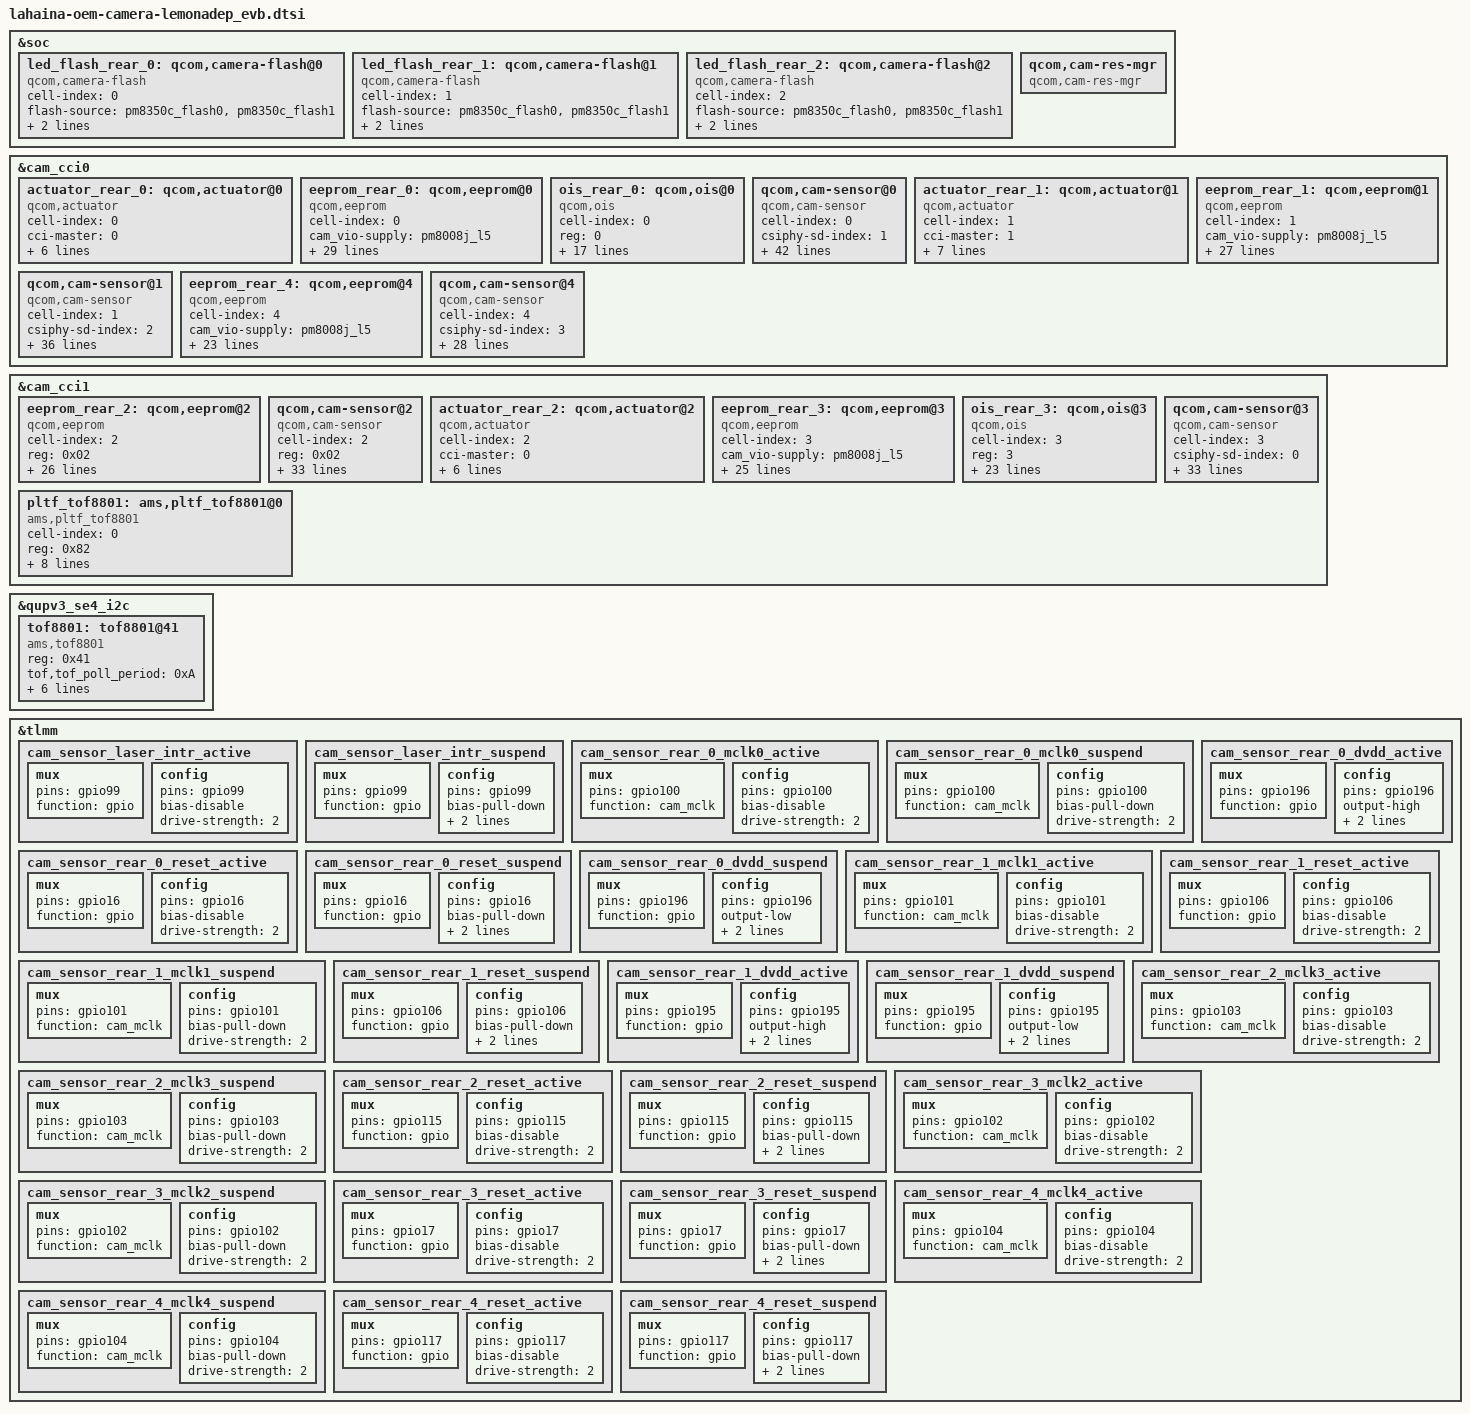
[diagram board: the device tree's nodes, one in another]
#include <dt-bindings/clock/qcom,camcc-lahaina.h>

&soc {
    led_flash_rear_0: qcom,camera-flash@0 {
        cell-index = <0>;
        compatible = "qcom,camera-flash";
        flash-source = <&pm8350c_flash0 &pm8350c_flash1>;
        torch-source = <&pm8350c_torch0 &pm8350c_torch1>;
        switch-source = <&pm8350c_switch2>;
        status = "ok";
    };

    led_flash_rear_1: qcom,camera-flash@1 {
        cell-index = <1>;
        compatible = "qcom,camera-flash";
        flash-source = <&pm8350c_flash0 &pm8350c_flash1>;
        torch-source = <&pm8350c_torch0 &pm8350c_torch1>;
        switch-source = <&pm8350c_switch2>;
        status = "ok";
    };

    led_flash_rear_2: qcom,camera-flash@2 {
        cell-index = <2>;
        compatible = "qcom,camera-flash";
        flash-source = <&pm8350c_flash0 &pm8350c_flash1>;
        torch-source = <&pm8350c_torch0 &pm8350c_torch1>;
        switch-source = <&pm8350c_switch2>;
        status = "ok";
    };

    qcom,cam-res-mgr {
        compatible = "qcom,cam-res-mgr";
        status = "ok";
    };
};

&cam_cci0 {

    actuator_rear_0: qcom,actuator@0 {
        cell-index = <0>;
        compatible = "qcom,actuator";
        cci-master = <0>;
        cam_vaf-supply = <&pm8008i_l7>;
        regulator-names = "cam_vaf";
        rgltr-cntrl-support;
        rgltr-min-voltage = <2800000>;
        rgltr-max-voltage = <2800000>;
        rgltr-load-current = <1000000>;
    };

    eeprom_rear_0: qcom,eeprom@0 {
        cell-index = <0>;
        compatible = "qcom,eeprom";
        cam_vio-supply = <&pm8008j_l5>;
        cam_vana-supply = <&pm8350c_bob>;
        cam_v_custom1-supply = <&pm8008i_l6>;
        cam_clk-supply = <&cam_cc_titan_top_gdsc>;
        cam_vaf-supply = <&pm8008i_l7>;
        regulator-names = "cam_vio", "cam_vana", "cam_v_custom1", "cam_clk", "cam_vaf";
        rgltr-cntrl-support;
        rgltr-min-voltage = <0 3200000 2700000 0 2800000>;
        rgltr-max-voltage = <0 3960000 3000000 0 2800000>;
        rgltr-load-current = <200000 2000000 1000000 0 1000000>;
        gpio-no-mux = <0>;
        pinctrl-names = "cam_default", "cam_suspend";
        pinctrl-0 = <&cam_sensor_rear_0_mclk0_active
                     &cam_sensor_rear_0_reset_active
                     &cam_sensor_rear_0_dvdd_active>;
        pinctrl-1 = <&cam_sensor_rear_0_mclk0_suspend
                     &cam_sensor_rear_0_reset_suspend
                     &cam_sensor_rear_0_dvdd_suspend>;
        gpios = <&tlmm 100 0>,
                <&tlmm 16 0>,
                <&tlmm 196 0>;
        gpio-reset = <1>;
        gpio-vdig = <2>;
        gpio-req-tbl-num = <0 1 2>;
        gpio-req-tbl-flags = <1 0 0>;
        gpio-req-tbl-label = "CAMIF_MCLK0",
                    "CAM_RESET0","CAM_DVDD0";
        cci-master = <0>;
        status = "ok";
        clocks = <&clock_camcc CAM_CC_MCLK0_CLK>;
        clock-names = "cam_clk";
        clock-cntl-level = "nominal";
        clock-rates = <19200000>;
    };

    ois_rear_0: qcom,ois@0{
        cell-index = <0>;
        reg = <0>;
        compatible = "qcom,ois";
        cam_vio-supply = <&pm8008j_l5>;
        cam_vaf-supply = <&pm8008i_l7>;
        cam_v_custom1-supply = <&pm8008i_l6>;
        regulator-names ="cam_vio","cam_vaf","cam_v_custom1";
        rgltr-cntrl-support;
        rgltr-min-voltage = <0 2800000 2700000>;
        rgltr-max-voltage = <0 2800000 3000000>;
        rgltr-load-current = <200000 1000000 2000000>;
        cci-master = <0>;
        ois_gyro,position=<3>;
        ois_gyro,type=<6>;
        ois,type=<0>;
        ois,name="LC898128";
        ois_module,vendor=<6>;
        ois_actuator,vednor=<1>;
        ois,fw=<1>;
        status = "ok";
    };

/*wide camera*/
    qcom,cam-sensor@0 {
        cell-index = <0>;
        compatible = "qcom,cam-sensor";
        csiphy-sd-index = <1>;
        sensor-position-roll = <90>;
        sensor-position-pitch = <0>;
        sensor-position-yaw = <180>;
        actuator-src = <&actuator_rear_0>;
        eeprom-src = <&eeprom_rear_0>;
        led-flash-src = <&led_flash_rear_0>;
        ois-src = <&ois_rear_0>;
        cam_vio-supply = <&pm8008j_l5>;
        cam_vana-supply = <&pm8350c_bob>;
        cam_v_custom1-supply = <&pm8008i_l6>;
        cam_clk-supply = <&cam_cc_titan_top_gdsc>;
        cam_bob-supply = <&pm8350c_bob>;
        cam_vaf-supply = <&pm8008i_l7>;
        regulator-names = "cam_vio", "cam_vana", "cam_v_custom1", "cam_clk", "cam_bob", "cam_vaf";
        rgltr-cntrl-support;
        rgltr-min-voltage = <0 3200000 2700000 0 3200000 2700000>;
        rgltr-max-voltage = <0 3960000 3000000 0 3960000 3000000>;
        rgltr-load-current = <200000 2000000 1000000 0 2000000 1000000>;
        gpio-no-mux = <0>;
        pinctrl-names = "cam_default", "cam_suspend";
        pinctrl-0 = <&cam_sensor_rear_0_mclk0_active
                     &cam_sensor_rear_0_reset_active
                     &cam_sensor_rear_0_dvdd_active>;
        pinctrl-1 = <&cam_sensor_rear_0_mclk0_suspend
                     &cam_sensor_rear_0_reset_suspend
                     &cam_sensor_rear_0_dvdd_suspend>;
        gpios = <&tlmm 100 0>,
                <&tlmm 16 0>,
                <&tlmm 196 0>;
        gpio-reset = <1>;
        gpio-vdig = <2>;
        gpio-req-tbl-num = <0 1 2>;
        gpio-req-tbl-flags = <1 0 0>;
        gpio-req-tbl-label = "CAMIF_MCLK0","CAM_RESET0","CAM_DVDD0";
        cci-master = <0>;
        status = "ok";
        clocks = <&clock_camcc CAM_CC_MCLK0_CLK>;
        clock-names = "cam_clk";
        clock-cntl-level = "nominal";
        clock-rates = <19200000>;
        is-support-laser = <1>;
        at-current-support = <1>;
    };

    actuator_rear_1: qcom,actuator@1 {
        cell-index = <1>;
        compatible = "qcom,actuator";
        cci-master = <1>;
        cam_vaf-supply = <&pm8008j_l3>;
        regulator-names = "cam_vaf";
        rgltr-cntrl-support;
        rgltr-min-voltage = <2800000>;
        rgltr-max-voltage = <2800000>;
        rgltr-load-current = <1000000>;
        need-check-pid;
    };

    eeprom_rear_1: qcom,eeprom@1 {
        cell-index = <1>;
        compatible = "qcom,eeprom";
        cam_vio-supply = <&pm8008j_l5>;
        cam_vana-supply = <&pm8350c_bob>;
        cam_clk-supply = <&cam_cc_titan_top_gdsc>;
        cam_vaf-supply = <&pm8008j_l3>;
        regulator-names = "cam_vio", "cam_vana", "cam_clk", "cam_vaf";
        rgltr-cntrl-support;
        rgltr-min-voltage = <0 3200000 0 2800000>;
        rgltr-max-voltage = <0 3960000 0 2800000>;
        rgltr-load-current = <200000 2000000 0 1000000>;
        gpio-no-mux = <0>;
        pinctrl-names = "cam_default", "cam_suspend";
        pinctrl-0 = <&cam_sensor_rear_1_mclk1_active
                     &cam_sensor_rear_1_reset_active
                     &cam_sensor_rear_1_dvdd_active>;
        pinctrl-1 = <&cam_sensor_rear_1_mclk1_suspend
                     &cam_sensor_rear_1_reset_suspend
                     &cam_sensor_rear_1_dvdd_suspend>;
        gpios = <&tlmm 101 0>,
                <&tlmm 106 0>,
                <&tlmm 195 0>;
        gpio-reset = <1>;
        gpio-vdig = <2>;
        gpio-req-tbl-num = <0 1 2>;
        gpio-req-tbl-flags = <1 0 0>;
        gpio-req-tbl-label = "CAMIF_MCLK1",
                    "CAM_RESET1","CAM_DVDD1";
        cci-master = <1>;
        status = "ok";
        clocks = <&clock_camcc CAM_CC_MCLK1_CLK>;
        clock-names = "cam_clk";
        clock-cntl-level = "nominal";
        clock-rates = <19200000>;
    };

    /*ultra wide camera*/
    qcom,cam-sensor@1 {
        cell-index = <1>;
        compatible = "qcom,cam-sensor";
        csiphy-sd-index = <2>;
        sensor-position-roll = <90>;
        sensor-position-pitch = <0>;
        sensor-position-yaw = <180>;
        eeprom-src = <&eeprom_rear_1>;
        actuator-src = <&actuator_rear_1>;
        led-flash-src = <&led_flash_rear_1>;
        cam_vio-supply = <&pm8008j_l5>;
        cam_vana-supply = <&pm8350c_bob>;
        cam_clk-supply = <&cam_cc_titan_top_gdsc>;
        cam_bob-supply = <&pm8350c_bob>;
        regulator-names = "cam_vio", "cam_vana", "cam_clk", "cam_bob";
        rgltr-cntrl-support;
        rgltr-min-voltage = <0 3200000 0 3200000>;
        rgltr-max-voltage = <0 3960000 0 3960000>;
        rgltr-load-current = <200000 2000000 0 2000000>;
        gpio-no-mux = <0>;
        pinctrl-names = "cam_default", "cam_suspend";
        pinctrl-0 = <&cam_sensor_rear_1_mclk1_active
                     &cam_sensor_rear_1_reset_active
                     &cam_sensor_rear_1_dvdd_active>;
        pinctrl-1 = <&cam_sensor_rear_1_mclk1_suspend
                     &cam_sensor_rear_1_reset_suspend
                     &cam_sensor_rear_1_dvdd_suspend>;
        gpios = <&tlmm 101 0>,
                <&tlmm 106 0>,
                <&tlmm 195 0>;
        gpio-reset = <1>;
        gpio-vdig = <2>;
        gpio-req-tbl-num = <0 1 2>;
        gpio-req-tbl-flags = <1 0 0>;
        gpio-req-tbl-label = "CAMIF_MCLK1","CAM_RESET1","CAM_DVDD1";
        cci-master = <1>;
        status = "ok";
        clocks = <&clock_camcc CAM_CC_MCLK1_CLK>;
        clock-names = "cam_clk";
        clock-cntl-level = "nominal";
        clock-rates = <19200000>;
        at-current-support = <1>;
        is-diff-af-support = <1>;
    };

    eeprom_rear_4: qcom,eeprom@4 {
        cell-index = <4>;
        compatible = "qcom,eeprom";
        cam_vio-supply = <&pm8008j_l5>;
        cam_vdig-supply = <&pm8008i_l2>;
        cam_clk-supply = <&cam_cc_titan_top_gdsc>;
        cam_vana-supply = <&pm8008i_l5>;
        regulator-names = "cam_vio", "cam_vdig", "cam_clk", "cam_vana";
        rgltr-cntrl-support;
        rgltr-min-voltage = <0 1170000 0 2800000>;
        rgltr-max-voltage = <0 2040000 0 2800000>;
        rgltr-load-current = <200000 680000 0 50000>;
        gpio-no-mux = <0>;
        pinctrl-names = "cam_default", "cam_suspend";
        pinctrl-0 = <&cam_sensor_rear_4_mclk4_active
                     &cam_sensor_rear_4_reset_active>;
        pinctrl-1 = <&cam_sensor_rear_4_mclk4_suspend
                     &cam_sensor_rear_4_reset_suspend>;
        gpios = <&tlmm 104 0>,
                <&tlmm 117 0>;
        gpio-reset = <1>;
        gpio-req-tbl-num = <0 1>;
        gpio-req-tbl-flags = <1 0>;
        gpio-req-tbl-label = "CAMIF_MCLK4",
                    "CAM_RESET4";
        cci-master = <1>;
        status = "ok";
        clocks = <&clock_camcc CAM_CC_MCLK4_CLK>;
        clock-names = "cam_clk";
        clock-cntl-level = "nominal";
        clock-rates = <19200000>;
    };

    /*forth_camera*/
    qcom,cam-sensor@4 {
        cell-index = <4>;
        compatible = "qcom,cam-sensor";
        csiphy-sd-index = <3>;
        eeprom-src = <&eeprom_rear_4>;
        sensor-position-roll = <90>;
        sensor-position-pitch = <0>;
        sensor-position-yaw = <180>;
        cam_vio-supply = <&pm8008j_l5>;
        cam_vdig-supply = <&pm8008i_l2>;
        cam_clk-supply = <&cam_cc_titan_top_gdsc>;
        cam_vana-supply = <&pm8008i_l5>;
        regulator-names = "cam_vio", "cam_vdig", "cam_clk", "cam_vana";
        rgltr-cntrl-support;
        rgltr-min-voltage = <0 1200000 0 2800000>;
        rgltr-max-voltage = <0 1200000 0 2800000>;
        rgltr-load-current = <200000 680000 0 50000>;
        gpio-no-mux = <0>;
        pinctrl-names = "cam_default", "cam_suspend";
        pinctrl-0 = <&cam_sensor_rear_4_mclk4_active
                     &cam_sensor_rear_4_reset_active>;
        pinctrl-1 = <&cam_sensor_rear_4_mclk4_suspend
                     &cam_sensor_rear_4_reset_suspend>;
        gpios = <&tlmm 104 0>,
                <&tlmm 117 0>;
        gpio-reset = <1>;
        gpio-req-tbl-num = <0 1>;
        gpio-req-tbl-flags = <1 0>;
        gpio-req-tbl-label = "CAMIF_MCLK4", "CAM_RESET4";
        cci-master = <1>;
        status = "ok";
        clocks = <&clock_camcc CAM_CC_MCLK4_CLK>;
        clock-names = "cam_clk";
        clock-cntl-level = "nominal";
        clock-rates = <19200000>;
    };
};

&cam_cci1 {
    eeprom_rear_2: qcom,eeprom@2 {
        cell-index = <2>;
        compatible = "qcom,eeprom";
        reg = <0x02>;
        cam_vio-supply = <&pm8008j_l5>;
        cam_vana-supply = <&pm8008i_l4>;
        cam_vdig-supply = <&pm8008j_l2>;
        cam_clk-supply = <&cam_cc_titan_top_gdsc>;
        regulator-names = "cam_vio", "cam_vana", "cam_vdig","cam_clk";
        rgltr-cntrl-support;
        rgltr-min-voltage = <0 2700000 950000 0>;
        rgltr-max-voltage = <0 2900000 1150000 0>;
        rgltr-load-current = <200000 35000 301000 0>;
        gpio-no-mux = <0>;
        pinctrl-names = "cam_default", "cam_suspend";
        pinctrl-0 = <&cam_sensor_rear_2_mclk3_active
                     &cam_sensor_rear_2_reset_active>;
        pinctrl-1 = <&cam_sensor_rear_2_mclk3_suspend
                     &cam_sensor_rear_2_reset_suspend>;
        gpios = <&tlmm 103 0>,
                <&tlmm 115 0>;
        gpio-reset = <1>;
        gpio-req-tbl-num = <0 1>;
        gpio-req-tbl-flags = <1 0>;
        gpio-req-tbl-label = "CAM_front_MCLK","CAM_front_RESET";
        sensor-mode = <0>;
        cci-master = <1>;
        status = "ok";
        clocks = <&clock_camcc CAM_CC_MCLK3_CLK>;
        clock-names = "cam_clk";
        clock-cntl-level = "nominal";
        clock-rates = <19200000>;
    };

/*front camera*/
    qcom,cam-sensor@2 {
        cell-index = <2>;
        compatible = "qcom,cam-sensor";
        reg = <0x02>;
        csiphy-sd-index = <5>;
        sensor-position-roll = <270>;
        sensor-position-pitch = <0>;
        sensor-position-yaw = <0>;
        eeprom-src = <&eeprom_rear_2>;
        cam_vio-supply = <&pm8008j_l5>;
        cam_vana-supply = <&pm8008i_l4>;
        cam_vdig-supply = <&pm8008j_l2>;
        cam_clk-supply = <&cam_cc_titan_top_gdsc>;
        cam_bob-supply = <&pm8350c_bob>;
        regulator-names = "cam_vio", "cam_vana", "cam_vdig","cam_clk", "cam_bob";
        rgltr-cntrl-support;
        rgltr-min-voltage = <0 2700000 950000 0 3200000>;
        rgltr-max-voltage = <0 2900000 1150000 0 3960000>;
        rgltr-load-current = <200000 35000 301000 0 2000000>;
        gpio-no-mux = <0>;
        pinctrl-names = "cam_default", "cam_suspend";
        pinctrl-0 = <&cam_sensor_rear_2_mclk3_active
                     &cam_sensor_rear_2_reset_active>;
        pinctrl-1 = <&cam_sensor_rear_2_mclk3_suspend
                     &cam_sensor_rear_2_reset_suspend>;
        gpios = <&tlmm 103 0>,
                <&tlmm 115 0>;
        gpio-reset = <1>;
        gpio-req-tbl-num = <0 1>;
        gpio-req-tbl-flags = <1 0>;
        gpio-req-tbl-label = "CAM_front_MCLK","CAM_front_RESET";
        sensor-mode = <0>;
        cci-master = <1>;
        status = "ok";
        clocks = <&clock_camcc CAM_CC_MCLK3_CLK>;
        clock-names = "cam_clk";
        clock-cntl-level = "nominal";
        clock-rates = <19200000>;
    };

    actuator_rear_2: qcom,actuator@2 {
        cell-index = <2>;
        compatible = "qcom,actuator";
        cci-master = <0>;
        cam_vaf-supply = <&pm8008j_l7>;
        regulator-names = "cam_vaf";
        rgltr-cntrl-support;
        rgltr-min-voltage = <2800000>;
        rgltr-max-voltage = <2800000>;
        rgltr-load-current = <1000000>;
    };

    eeprom_rear_3: qcom,eeprom@3 {
        cell-index = <3>;
        compatible = "qcom,eeprom";
        cam_vio-supply = <&pm8008j_l5>;
        cam_vana-supply = <&pm8008i_l3>;
        cam_vdig-supply = <&pm8008i_l1>;
        cam_clk-supply = <&cam_cc_titan_top_gdsc>;
        cam_vaf-supply = <&pm8008j_l7>;
        regulator-names = "cam_vio", "cam_vana", "cam_vdig",
            "cam_clk", "cam_vaf";
        rgltr-cntrl-support;
        rgltr-min-voltage = <0 2700000 950000 0 2800000>;
        rgltr-max-voltage = <0 2900000 1150000 0 2800000>;
        rgltr-load-current = <200000 52000 140000 0 1000000>;
        gpio-no-mux = <0>;
        pinctrl-names = "cam_default", "cam_suspend";
        pinctrl-0 = <&cam_sensor_rear_3_mclk2_active
                     &cam_sensor_rear_3_reset_active>;
        pinctrl-1 = <&cam_sensor_rear_3_mclk2_suspend
                     &cam_sensor_rear_3_reset_suspend>;
        gpios = <&tlmm 102 0>,
                <&tlmm 17 0>;
        gpio-reset = <1>;
        gpio-req-tbl-num = <0 1>;
        gpio-req-tbl-flags = <1 0>;
        gpio-req-tbl-label = "CAMIF_MCLK2", "CAM_RESET2";
        cci-master = <0>;
        status = "ok";
        clocks = <&clock_camcc CAM_CC_MCLK2_CLK>;
        clock-names = "cam_clk";
        clock-cntl-level = "nominal";
        clock-rates = <19200000>;
    };

    ois_rear_3: qcom,ois@3{
        cell-index = <3>;
        reg = <3>;
        compatible = "qcom,ois";
        cam_vio-supply = <&pm8008j_l5>;
        cam_vana-supply = <&pm8008i_l3>;
        cam_vdig-supply = <&pm8008i_l1>;
        cam_vaf-supply = <&pm8008j_l6>;
        cam_v_custom1-supply = <&pm8008i_l7>;
        cam_v_custom2-supply = <&pm8008i_l6>;
        regulator-names = "cam_vio","cam_vana","cam_vdig","cam_vaf","cam_v_custom1","cam_v_custom2";
        rgltr-cntrl-support;
        rgltr-min-voltage = <0 2700000 950000 2700000 2800000 2700000>;
        rgltr-max-voltage = <0 2900000 1150000 3000000 2800000 3000000>;
        rgltr-load-current = <200000 52000 140000 2000000 1000000 2000000>;
        cci-master = <0>;
        ois_gyro,position=<3>;
        ois_gyro,type=<3>;
        ois,type=<1>;
        ois,name="LC898124";
        ois_module,vendor=<0>;
        ois_actuator,vednor=<0>;
        ois,fw=<1>;
        status = "ok";
    };

/*tele camera*/
    qcom,cam-sensor@3 {
        cell-index = <3>;
        compatible = "qcom,cam-sensor";
        csiphy-sd-index = <0>;
        sensor-position-roll = <90>;
        sensor-position-pitch = <0>;
        sensor-position-yaw = <180>;
        eeprom-src = <&eeprom_rear_3>;
        actuator-src = <&actuator_rear_2>;
        led-flash-src = <&led_flash_rear_2>;
        ois-src = <&ois_rear_3>;
        cam_vio-supply = <&pm8008j_l5>;
        cam_vana-supply = <&pm8008i_l3>;
        cam_vdig-supply = <&pm8008i_l1>;
        cam_clk-supply = <&cam_cc_titan_top_gdsc>;
        cam_bob-supply = <&pm8350c_bob>;
        regulator-names = "cam_vio", "cam_vana", "cam_vdig",
            "cam_clk", "cam_bob";
        rgltr-cntrl-support;
        rgltr-min-voltage = <0 2700000 950000 0 3200000>;
        rgltr-max-voltage = <0 2900000 1150000 0 3960000>;
        rgltr-load-current = <200000 52000 140000 0 2000000>;
        gpio-no-mux = <0>;
        pinctrl-names = "cam_default", "cam_suspend";
        pinctrl-0 = <&cam_sensor_rear_3_mclk2_active
                     &cam_sensor_rear_3_reset_active>;
        pinctrl-1 = <&cam_sensor_rear_3_mclk2_suspend
                     &cam_sensor_rear_3_reset_suspend>;
        gpios = <&tlmm 102 0>,
                <&tlmm 17 0>;
        gpio-reset = <1>;
        gpio-req-tbl-num = <0 1>;
        gpio-req-tbl-flags = <1 0>;
        gpio-req-tbl-label = "CAMIF_MCLK2", "CAM_RESET2";
        cci-master = <0>;
        status = "ok";
        clocks = <&clock_camcc CAM_CC_MCLK2_CLK>;
        clock-names = "cam_clk";
        clock-cntl-level = "nominal";
        clock-rates = <19200000>;
    };

pltf_tof8801: ams,pltf_tof8801@0 {
        cell-index = <0>;
        reg = <0x82>;
        compatible = "ams,pltf_tof8801";
        cam_vio-supply = <&pm8008j_l5>;
        regulator-names = "cam_vio";
        rgltr-cntrl-support;
        rgltr-min-voltage = <0>;
        rgltr-max-voltage = <0>;
        rgltr-load-current = <5000>;
        cci-device = <1>;
        cci-master = <1>;
        status = "ok";
	};
};

&qupv3_se4_i2c {
    tof8801: tof8801@41 {
        compatible = "ams,tof8801";
        reg = <0x41>;
        tof,tof_poll_period = <0xA>; /*poll period (100 usec)*/
        laser_vdd-supply = <&pm8008j_l4>;
        pinctrl-names = "laser_default", "laser_suspend";
        pinctrl-0 = <&cam_sensor_laser_intr_active>;
        pinctrl-1 = <&cam_sensor_laser_intr_suspend>;
        interrupt-parent = <&tlmm>;
        enable-gpios = <&tlmm 126 0>;
        irq-gpios = <&tlmm 99 0>;
    };

};

&tlmm {
     cam_sensor_laser_intr_active:cam_sensor_laser_intr_active {
        mux {
            pins = "gpio99";
            function = "gpio";
        };

        config {
            pins = "gpio99";
            bias-disable; /* No PULL */
            drive-strength = <2>; /* 2 MA */
        };
    };

    cam_sensor_laser_intr_suspend: cam_sensor_laser_intr_suspend {
        mux {
            pins = "gpio99";
            function = "gpio";
        };

        config {
            pins = "gpio99";
            bias-pull-down; /* PULL DOWN */
            drive-strength = <2>; /* 2 MA */
            output-low;
        };
    };
    cam_sensor_rear_0_mclk0_active: cam_sensor_rear_0_mclk0_active {
        /* MCLK0 */
        mux {
            pins = "gpio100";
            function = "cam_mclk";
        };

        config {
            pins = "gpio100";
            bias-disable; /* No PULL */
            drive-strength = <2>; /* 2 MA */
        };
    };

    cam_sensor_rear_0_mclk0_suspend: cam_sensor_rear_0_mclk0_suspend {
        /* MCLK0 */
        mux {
            pins = "gpio100";
            function = "cam_mclk";
        };

        config {
            pins = "gpio100";
            bias-pull-down; /* PULL DOWN */
            drive-strength = <2>; /* 2 MA */
        };
    };

    cam_sensor_rear_0_reset_active: cam_sensor_rear_0_reset_active {
        /* RESET REARAUX */
        mux {
            pins = "gpio16";
            function = "gpio";
        };

        config {
            pins = "gpio16";
            bias-disable; /* No PULL */
            drive-strength = <2>; /* 2 MA */
        };
    };

    cam_sensor_rear_0_reset_suspend: cam_sensor_rear_0_reset_suspend {
        /* RESET REARAUX */
        mux {
            pins = "gpio16";
            function = "gpio";
        };

        config {
            pins = "gpio16";
            bias-pull-down; /* PULL DOWN */
            drive-strength = <2>; /* 2 MA */
            output-low;
        };
    };

    cam_sensor_rear_0_dvdd_active: cam_sensor_rear_0_dvdd_active {
        /* RESET, STANDBY */
        mux {
            pins = "gpio196";
            function = "gpio";
        };

        config {
            pins = "gpio196";
            output-high;
            bias-pull-up;
            drive-strength = <2>; /* 2 MA */
        };
    };

    cam_sensor_rear_0_dvdd_suspend: cam_sensor_rear_0_dvdd_suspend {
        /* RESET, STANDBY */
        mux {
            pins = "gpio196";
            function = "gpio";
        };

        config {
            pins = "gpio196";
            output-low; /* active low reset */
            bias-pull-down;
            drive-strength = <2>; /* 2 MA */
        };
    };

    cam_sensor_rear_1_mclk1_active: cam_sensor_rear_1_mclk1_active {
        /* MCLK1 */
        mux {
            pins = "gpio101";
            function = "cam_mclk";
        };

        config {
            pins = "gpio101";
            bias-disable; /* No PULL */
            drive-strength = <2>; /* 2 MA */
        };
    };

    cam_sensor_rear_1_mclk1_suspend: cam_sensor_rear_1_mclk1_suspend {
        /* MCLK1 */
        mux {
            pins = "gpio101";
            function = "cam_mclk";
        };

        config {
            pins = "gpio101";
            bias-pull-down; /* PULL DOWN */
            drive-strength = <2>; /* 2 MA */
        };
    };

    cam_sensor_rear_1_reset_active: cam_sensor_rear_1_reset_active {
        /* RESET 2 */
        mux {
            pins = "gpio106";
            function = "gpio";
        };

        config {
            pins = "gpio106";
            bias-disable; /* No PULL */
            drive-strength = <2>; /* 2 MA */
        };
    };

    cam_sensor_rear_1_reset_suspend: cam_sensor_rear_1_reset_suspend {
        /* RESET 2 */
        mux {
            pins = "gpio106";
            function = "gpio";
        };

        config {
            pins = "gpio106";
            bias-pull-down; /* PULL DOWN */
            drive-strength = <2>; /* 2 MA */
            output-low;
        };
    };

    cam_sensor_rear_1_dvdd_active: cam_sensor_rear_1_dvdd_active {
        /* RESET, STANDBY */
        mux {
            pins = "gpio195";
            function = "gpio";
        };

        config {
            pins = "gpio195";
            output-high;
            bias-pull-up;
            drive-strength = <2>; /* 2 MA */
        };
    };

    cam_sensor_rear_1_dvdd_suspend: cam_sensor_rear_1_dvdd_suspend {
        /* RESET, STANDBY */
        mux {
            pins = "gpio195";
            function = "gpio";
        };

        config {
            pins = "gpio195";
            output-low; /* active low reset */
            bias-pull-down;
            drive-strength = <2>; /* 2 MA */
        };
    };

    cam_sensor_rear_2_mclk3_active: cam_sensor_rear_2_mclk3_active {
        /* MCLK3 */
        mux {
            pins = "gpio103";
            function = "cam_mclk";
        };

        config {
            pins = "gpio103";
            bias-disable; /* No PULL */
            drive-strength = <2>; /* 2 MA */
        };
    };

    cam_sensor_rear_2_mclk3_suspend: cam_sensor_rear_2_mclk3_suspend {
        /* MCLK3 */
        mux {
            pins = "gpio103";
            function = "cam_mclk";
        };

        config {
            pins = "gpio103";
            bias-pull-down; /* PULL DOWN */
            drive-strength = <2>; /* 2 MA */
        };
    };

    cam_sensor_rear_2_reset_active: cam_sensor_rear_2_reset_active {
        /* RESET 5 */
        mux {
            pins = "gpio115";
            function = "gpio";
        };

        config {
            pins = "gpio115";
            bias-disable; /* No PULL */
            drive-strength = <2>; /* 2 MA */
        };
    };

    cam_sensor_rear_2_reset_suspend: cam_sensor_rear_2_reset_suspend {
        /* RESET 5 */
        mux {
            pins = "gpio115";
            function = "gpio";
        };

        config {
            pins = "gpio115";
            bias-pull-down; /* PULL DOWN */
            drive-strength = <2>; /* 2 MA */
            output-low;
        };
    };

    cam_sensor_rear_3_mclk2_active: cam_sensor_rear_3_mclk2_active {
        /* MCLK2 */
        mux {
            pins = "gpio102";
            function = "cam_mclk";
        };

        config {
            pins = "gpio102";
            bias-disable; /* No PULL */
            drive-strength = <2>; /* 2 MA */
        };
    };

    cam_sensor_rear_3_mclk2_suspend: cam_sensor_rear_3_mclk2_suspend {
        /* MCLK2 */
        mux {
            pins = "gpio102";
            function = "cam_mclk";
        };

        config {
            pins = "gpio102";
            bias-pull-down; /* PULL DOWN */
            drive-strength = <2>; /* 2 MA */
        };
    };

    cam_sensor_rear_3_reset_active: cam_sensor_rear_3_reset_active {
        /* RESET REAR */
        mux {
            pins = "gpio17";
            function = "gpio";
        };

        config {
            pins = "gpio17";
            bias-disable; /* No PULL */
            drive-strength = <2>; /* 2 MA */
        };
    };

    cam_sensor_rear_3_reset_suspend: cam_sensor_rear_3_reset_suspend {
        /* RESET REAR */
        mux {
            pins = "gpio17";
            function = "gpio";
        };

        config {
            pins = "gpio17";
            bias-pull-down; /* PULL DOWN */
            drive-strength = <2>; /* 2 MA */
            output-low;
        };
    };


    cam_sensor_rear_4_mclk4_active: cam_sensor_rear_4_mclk4_active {
        /* MCLK4 */
        mux {
            pins = "gpio104";
            function = "cam_mclk";
        };

        config {
            pins = "gpio104";
            bias-disable; /* No PULL */
            drive-strength = <2>; /* 2 MA */
        };
    };

    cam_sensor_rear_4_mclk4_suspend: cam_sensor_rear_4_mclk4_suspend {
        /* MCLK4 */
        mux {
            pins = "gpio104";
            function = "cam_mclk";
        };

        config {
            pins = "gpio104";
            bias-pull-down; /* PULL DOWN */
            drive-strength = <2>; /* 2 MA */
        };
    };

    cam_sensor_rear_4_reset_active: cam_sensor_rear_4_reset_active {
        /* RESET 3 */
        mux {
            pins = "gpio117";
            function = "gpio";
        };

        config {
            pins = "gpio117";
            bias-disable; /* No PULL */
            drive-strength = <2>; /* 2 MA */
        };
    };

    cam_sensor_rear_4_reset_suspend: cam_sensor_rear_4_reset_suspend {
        /* RESET 3 */
        mux {
            pins = "gpio117";
            function = "gpio";
        };

        config {
            pins = "gpio117";
            bias-pull-down; /* PULL DOWN */
            drive-strength = <2>; /* 2 MA */
            output-low;
        };
    };

};
